# OTTOCAL_OTTOCAL_502E0000h register map
Vendor: Texas Instruments
Peripheral module from a debugger description file (folder AM261x).
Registers are 16-bit, read-write, reset 0x0 unless marked. A register's access mark holds for its fields unless they carry their own. Offsets are as the file gives them; lines under a group give offsets from that group; [hi:lo] are bit positions; {n}, {i} and the like mark numbered series; 'fields as' and 'values as' point back to an identical list; <NAME> marks a mode.

## OTTOCAL
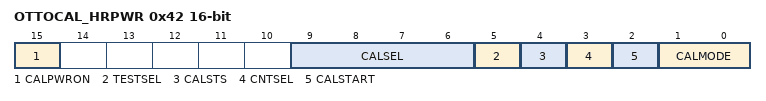
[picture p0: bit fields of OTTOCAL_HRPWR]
0x42 OTTOCAL_HRPWR access per field — HRPWM Power Register This register is only accessible on EPWM modules with HRPWM capabilities.
  [15] CALPWRON rw — MEP Calibration Power Bits [only available on ePWM1] 0:Disables MEP calibration logic in the HRPWM and reduces power consumption. 1:Enables MEP calibration logic
  [9:6] CALSEL rw — EPWM Delay Line Selection for Calibration:
  [5] TESTSEL rw — Test Mode Select Bit: This bit selects if a dummy delay is added in Oscillator Calibration mode to help reducing frequency when small delays are used:
  [4] CALSTS ro — Calibration Status Bit: This bit, when set to 1, indicates that calibration is in progress. It is set to 0 when:
  [3] CNTSEL rw — Counter Select Bit: Functionality of this bit has changed. When HRCNT0 or HRCNT1 reaches 0xFFFF, both counters are frozen. This bit will have an effect on when calibration starts:
  [2] CALSTART rw — Calibration Start/Stop Bit:
  [1:0] CALMODE rw — Note: CALMODE bits in HRPWM Module. Not used here.
0x44 OTTOCAL_HRCAL — HRPWM Calibration Register.
  [7:0] HRCAL — These 8-bits are used to select the number of delay elements during oscillator calibration for the calibration delay line [DCAL] only. The user configures the desired delay and then initiates a calibration run. Based on the calibration run result, the delay is increased/decreased for the next calibration run.
0x46 OTTOCAL_HRPRD — HRPWM Period Register.
  [15:0] HRPRD — These 8-bits are used to select the number of delay elements during oscillator calibration for the calibration delay line [DCAL] only.
0x48 OTTOCAL_HRCNT0 — HRPWM Counter 0 Register.
  [15:0] HRCNT0 — The HRCNT0 counter increments on every ring oscillator clock pulse.
0x4A OTTOCAL_HRCNT1 — HRPWM Counter 1 Register.
  [15:0] HRCNT1 — The HRCNT1 counter increments on every system clock pulse.
0x4C OTTOCAL_HRMSTEP — HRPWM MEP Step Register This register is only accessible on EPWM modules with HRPWM capabilities. Only 16 bit accesses are allowed for this register. Debugger access in 32 bit mode may display incorrect values.
  [7:0] HRMSTEP — High Resolution MEP Step When auto-conversion is enabled [HRCNFG[AUTOCONV] = 1], This 8-bit field contains the MEP_ScaleFactor [number of MEP steps per coarse steps] used by the hardware to automatically convert the value in the CMPAHR, CMPBHR, DBFEDHR, DBREDHR , TBPHSHR, or TBPRDHR register to a scaled micro-edge delay on the high-resolution ePWM output. The value in this register is written by the SFO calibration software at the end of each calibration run.
